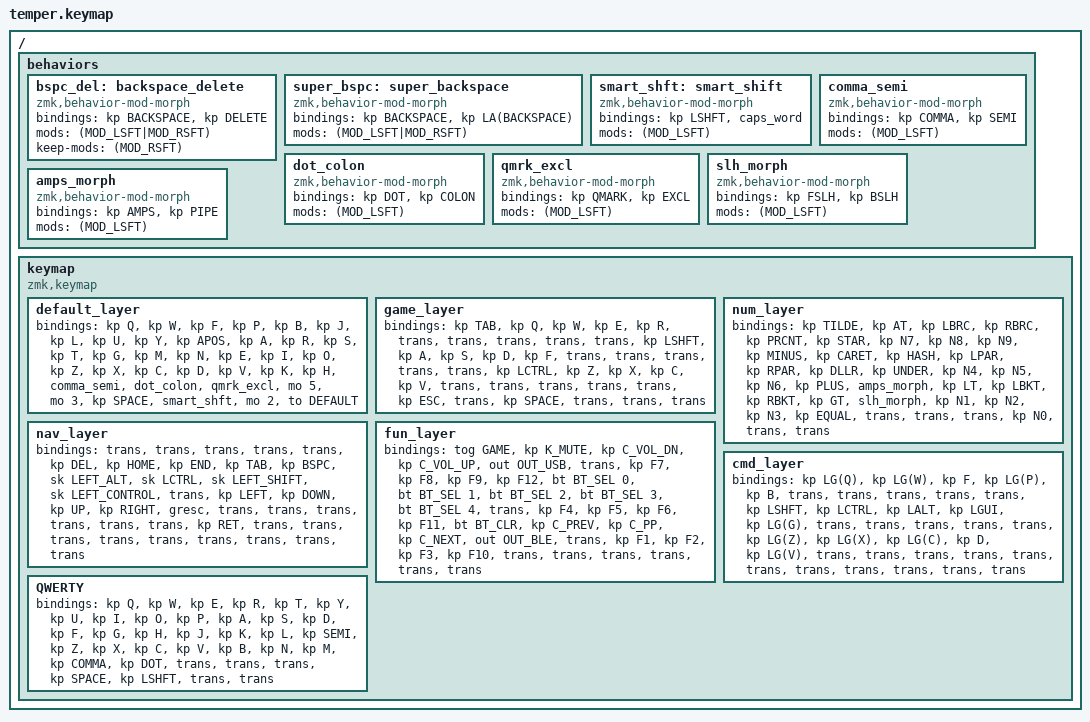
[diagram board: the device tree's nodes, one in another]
/*
 * Copyright (c) 2020 The ZMK Contributors
 *
 * SPDX-License-Identifier: MIT
 */

#include <behaviors.dtsi>
#include <dt-bindings/zmk/bt.h>
#include <dt-bindings/zmk/keys.h>
#include <dt-bindings/zmk/outputs.h>

/*
#define DEFAULT 0
#define GAME 1
#define NUM 2
#define NAV 3
#define FUN 4
#define CMD 5

# define &trans &trans
*/

/ {
    /*
    conditional_layers {
        compatible = "zmk,conditional-layers";
        tri_layer {
            if-layers = 3;
            then-layer = 4;
        };
    };
    */

    behaviors {
        bspc_del: backspace_delete {
            compatible = "zmk,behavior-mod-morph";
            #binding-cells = <0>;
            bindings = <&kp BACKSPACE>, <&kp DELETE>;

            mods = <(MOD_LSFT|MOD_RSFT)>;
            keep-mods = <(MOD_RSFT)>;
        };

        super_bspc: super_backspace {
            compatible = "zmk,behavior-mod-morph";
            #binding-cells = <0>;
            bindings = <&kp BACKSPACE>, <&kp LA(BACKSPACE)>;

            mods = <(MOD_LSFT|MOD_RSFT)>;
        };

        smart_shft: smart_shift {
            compatible = "zmk,behavior-mod-morph";
            #binding-cells = <0>;
            bindings = <&kp LSHFT>, <&caps_word>;

            mods = <(MOD_LSFT)>;
        };

        comma_semi: comma_semi {
            compatible = "zmk,behavior-mod-morph";
            #binding-cells = <0>;
            bindings = <&kp COMMA>, <&kp SEMI>;

            mods = <(MOD_LSFT)>;
        };

        dot_colon: dot_colon {
            compatible = "zmk,behavior-mod-morph";
            #binding-cells = <0>;
            bindings = <&kp DOT>, <&kp COLON>;

            mods = <(MOD_LSFT)>;
        };

        qmrk_excl: qmrk_excl {
            compatible = "zmk,behavior-mod-morph";
            #binding-cells = <0>;
            bindings = <&kp QMARK>, <&kp EXCL>;

            mods = <(MOD_LSFT)>;
        };

        slh_morph: slh_morph {
            compatible = "zmk,behavior-mod-morph";
            #binding-cells = <0>;
            bindings = <&kp FSLH>, <&kp BSLH>;

            mods = <(MOD_LSFT)>;
        };

        amps_morph: amps_morph {
            compatible = "zmk,behavior-mod-morph";
            #binding-cells = <0>;
            bindings = <&kp AMPS>, <&kp PIPE>;

            mods = <(MOD_LSFT)>;
        };
    };

    keymap {
        compatible = "zmk,keymap";

        default_layer {
            bindings = <
&kp Q  &kp W  &kp F  &kp P  &kp B  &kp J  &kp L  &kp U  &kp Y  &kp APOS  &kp A  &kp R  &kp S  &kp T  &kp G  &kp M  &kp N  &kp E  &kp I  &kp O  &kp Z  &kp X  &kp C  &kp D  &kp V  &kp K  &kp H  &comma_semi  &dot_colon  &qmrk_excl  &mo 5  &mo 3  &kp SPACE  &smart_shft  &mo 2  &to DEFAULT
            >;
        };

        game_layer {
            bindings = <
&kp TAB  &kp Q  &kp W  &kp E  &kp R  &trans  &trans  &trans  &trans  &trans  &kp LSHFT  &kp A  &kp S  &kp D  &kp F  &trans  &trans  &trans  &trans  &trans  &kp LCTRL  &kp Z  &kp X  &kp C  &kp V  &trans  &trans  &trans  &trans  &trans  &kp ESC  &trans  &kp SPACE  &trans  &trans  &trans
            >;
        };

        num_layer {
            bindings = <
&kp TILDE  &kp AT  &kp LBRC  &kp RBRC  &kp PRCNT  &kp STAR  &kp N7  &kp N8  &kp N9  &kp MINUS  &kp CARET  &kp HASH  &kp LPAR  &kp RPAR  &kp DLLR  &kp UNDER  &kp N4  &kp N5  &kp N6  &kp PLUS  &amps_morph  &kp LT  &kp LBKT  &kp RBKT  &kp GT  &slh_morph  &kp N1  &kp N2  &kp N3  &kp EQUAL  &trans  &trans  &trans  &kp N0  &trans  &trans
            >;
        };

        nav_layer {
            bindings = <
&trans  &trans  &trans  &trans  &trans  &kp DEL  &kp HOME  &kp END  &kp TAB  &kp BSPC  &sk LEFT_ALT  &sk LCTRL  &sk LEFT_SHIFT  &sk LEFT_CONTROL  &trans  &kp LEFT  &kp DOWN  &kp UP  &kp RIGHT  &gresc  &trans  &trans  &trans  &trans  &trans  &trans  &kp RET  &trans  &trans  &trans  &trans  &trans  &trans  &trans  &trans  &trans
            >;
        };

        fun_layer {
            bindings = <
&tog GAME  &kp K_MUTE  &kp C_VOL_DN  &kp C_VOL_UP  &out OUT_USB  &trans  &kp F7  &kp F8  &kp F9  &kp F12  &bt BT_SEL 0  &bt BT_SEL 1  &bt BT_SEL 2  &bt BT_SEL 3  &bt BT_SEL 4  &trans  &kp F4  &kp F5  &kp F6  &kp F11  &bt BT_CLR  &kp C_PREV  &kp C_PP  &kp C_NEXT  &out OUT_BLE  &trans  &kp F1  &kp F2  &kp F3  &kp F10  &trans  &trans  &trans  &trans  &trans  &trans
            >;
        };

        cmd_layer {
            bindings = <
&kp LG(Q)  &kp LG(W)  &kp F  &kp LG(P)  &kp B  &trans  &trans  &trans  &trans  &trans  &kp LSHFT  &kp LCTRL  &kp LALT  &kp LGUI  &kp LG(G)  &trans  &trans  &trans  &trans  &trans  &kp LG(Z)  &kp LG(X)  &kp LG(C)  &kp D  &kp LG(V)  &trans  &trans  &trans  &trans  &trans  &trans  &trans  &trans  &trans  &trans  &trans
            >;
        };

        QWERTY {
            bindings = <
&kp Q  &kp W  &kp E  &kp R  &kp T  &kp Y  &kp U  &kp I  &kp O  &kp P  &kp A  &kp S  &kp D  &kp F  &kp G  &kp H  &kp J  &kp K  &kp L  &kp SEMI  &kp Z  &kp X  &kp C  &kp V  &kp B  &kp N  &kp M  &kp COMMA  &kp DOT  &trans  &trans  &trans  &kp SPACE  &kp LSHFT  &trans  &trans
            >;
        };
    };
};
